AUTOSAR XML (schema 00044)
package /E40_Platform_System_SystemPackage/Components
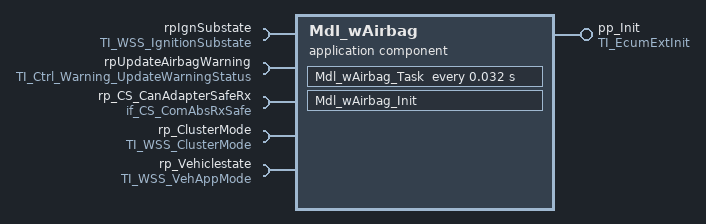
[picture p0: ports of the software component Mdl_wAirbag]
  application sw component type Mdl_wAirbag
    provide port pp_Init: server-com-spec{operation=Init, queue-length=1}, provided-interface=TI_EcumExtInit
    5 x require port:
      rpIgnSubstate: nonqueued-receiver-com-spec{data-element=IgnitionSubstate, init-value=constant-reference=Mdl_wAirbagIgnitionSubstateValue0}, required-interface=TI_WSS_IgnitionSubstate
      rpUpdateAirbagWarning: client-com-spec=UpdateWarningStatus, required-interface=TI_Ctrl_Warning_UpdateWarningStatus
      rp_CS_CanAdapterSafeRx: required-interface=if_CS_ComAbsRxSafe
        required-com-specs:
          RxCan_GetSignalValue
          RxCan_GetSignalValueU8Arr
          RxCan_SetSignalInitValue
          RxCan_SetSignalInitValueU8Arr
          RxCan_SignalClearJustRcvdStatus
          RxCan_SignalGetJustRcvdStatus
          RxCan_SignalInvalidProcessingControl
          RxCan_SignalMissingProcessingControl
          RxCan_SignalNRProcessingControl
      rp_ClusterMode: nonqueued-receiver-com-spec{data-element=WSSCurrentClusterMode, init-value=constant-reference=Mdl_wAirbagWSSCurrentClusterModeValue0}, required-interface=TI_WSS_ClusterMode
      rp_Vehiclestate: nonqueued-receiver-com-spec{data-element=WSSCurrentVehicleState, init-value=constant-reference=Mdl_wAirbagWSSCurrentVehicleStateValue0}, required-interface=TI_WSS_VehAppMode
    behavior IB_Mdl_wAirbag
      operation invoked event OIE_pp_Init_Mdl_wAirbag_InitTrigByInit: start-on-event=Mdl_wAirbag_Init, operation=pp_Init.Init
      timing event TEMdl_wAirbag_Task: start-on-event=Mdl_wAirbag_Task, period=0.032
      port-api-options:
        enable-take-address=false, indirect-api=false, port=pp_Init
        enable-take-address=false, indirect-api=false, port=rpIgnSubstate
        enable-take-address=false, indirect-api=false, port=rpUpdateAirbagWarning
        enable-take-address=false, indirect-api=false, port=rp_CS_CanAdapterSafeRx
        enable-take-address=false, indirect-api=false, port=rp_ClusterMode
        enable-take-address=false, indirect-api=false, port=rp_Vehiclestate
      runnable Mdl_wAirbag_Init: can-be-invoked-concurrently=true
      runnable Mdl_wAirbag_Task: can-be-invoked-concurrently=true
        data-receive-point-by-arguments:
          access DRA_rpIgnSubstate_IgnitionSubstate: accessed-variable=rpIgnSubstate.IgnitionSubstate
          access DRA_rp_ClusterMode_WSSCurrentClusterMode: accessed-variable=rp_ClusterMode.WSSCurrentClusterMode
          access DRA_rp_Vehiclestate_WSSCurrentVehicleState: accessed-variable=rp_Vehiclestate.WSSCurrentVehicleState
        10 x sync call:
          OA_rpUpdateAirbagWarning_UpdateWarningStatus: operation=rpUpdateAirbagWarning.UpdateWarningStatus
          OA_rp_CS_CanAdapterSafeRx_RxCan_GetSignalValueU8Arr: operation=rp_CS_CanAdapterSafeRx.RxCan_GetSignalValueU8Arr
          OA_rp_CS_CanAdapterSafeRx_RxCan_SetSignalInitValue: operation=rp_CS_CanAdapterSafeRx.RxCan_SetSignalInitValue
          OA_rp_CS_CanAdapterSafeRx_RxCan_SetSignalInitValueU8Arr: operation=rp_CS_CanAdapterSafeRx.RxCan_SetSignalInitValueU8Arr
          OA_rp_CS_CanAdapterSafeRx_RxCan_SignalInvalidProcessingControl: operation=rp_CS_CanAdapterSafeRx.RxCan_SignalInvalidProcessingControl
          OA_rp_CS_CanAdapterSafeRx_RxCan_SignalMissingProcessingControl: operation=rp_CS_CanAdapterSafeRx.RxCan_SignalMissingProcessingControl
          OA_rp_CS_CanAdapterSafeRx_RxCan_SignalNRProcessingControl: operation=rp_CS_CanAdapterSafeRx.RxCan_SignalNRProcessingControl
          OA_rp_CS_CanAdapterSafeRx_RxCan_SignalGetJustRcvdStatus: operation=rp_CS_CanAdapterSafeRx.RxCan_SignalGetJustRcvdStatus
          OA_rp_CS_CanAdapterSafeRx_RxCan_SignalClearJustRcvdStatus: operation=rp_CS_CanAdapterSafeRx.RxCan_SignalClearJustRcvdStatus
          OA_rp_CS_CanAdapterSafeRx_RxCan_GetSignalValue: operation=rp_CS_CanAdapterSafeRx.RxCan_GetSignalValue
  swc implementation IMPL_Mdl_wAirbag: behavior=IB_Mdl_wAirbag
